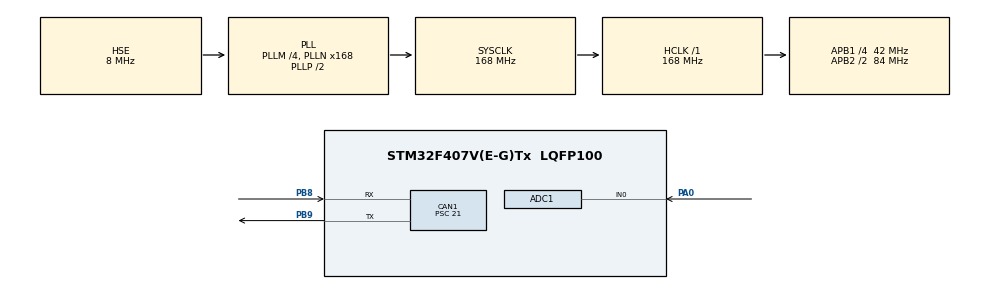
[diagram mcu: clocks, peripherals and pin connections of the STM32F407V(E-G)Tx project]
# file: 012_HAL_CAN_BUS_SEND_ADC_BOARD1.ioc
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Mcu.Family=STM32F4
RCC.PLLSourceVirtual=RCC_PLLSOURCE_HSE
PH0-OSC_IN.Signal=RCC_OSC_IN
Dma.ADC1.0.Instance=DMA2_Stream0
RCC.CortexFreq_Value=168000000
ADC1.ContinuousConvMode=ENABLE
CAN1.CalculateBaudRate=117647
RCC.APB1CLKDivider=RCC_HCLK_DIV4
RCC.SYSCLKSource=RCC_SYSCLKSOURCE_PLLCLK
ProjectManager.StackSize=0x400
PA0-WKUP.Signal=ADCx_IN0
Dma.ADC1.0.PeriphDataAlignment=DMA_PDATAALIGN_BYTE
CAN1.BS2=CAN_BS2_4TQ
ADC1.Channel-5\#ChannelRegularConversion=ADC_CHANNEL_0
CAN1.BS1=CAN_BS1_12TQ
ProjectManager.TargetToolchain=STM32CubeIDE
Dma.ADC1.0.Mode=DMA_CIRCULAR
RCC.HCLKFreq_Value=168000000
ADC1.Resolution=ADC_RESOLUTION_8B
PB9.Mode=CAN_Activate
Dma.ADC1.0.Priority=DMA_PRIORITY_LOW
RCC.APB2TimFreq_Value=168000000
Dma.ADC1.0.Direction=DMA_PERIPH_TO_MEMORY
ADC1.InjNumberOfConversion=0
NVIC.DMA2_Stream0_IRQn=true\:0\:0\:false\:false\:true\:false\:true
RCC.LSE_VALUE=32768
Dma.ADC1.0.MemDataAlignment=DMA_MDATAALIGN_BYTE
RCC.AHBFreq_Value=168000000
PH0-OSC_IN.Mode=HSE-External-Oscillator
RCC.HSE_VALUE=8000000
board=custom
RCC.VCOOutputFreq_Value=336000000
RCC.APB2Freq_Value=84000000
Dma.ADC1.0.PeriphInc=DMA_PINC_DISABLE
PH1-OSC_OUT.Signal=RCC_OSC_OUT
SH.ADCx_IN0.0=ADC1_IN0,IN0
ADC1.DMAContinuousRequests=ENABLE
ADC1.NbrOfConversion=1
Mcu.Name=STM32F407V(E-G)Tx
PH1-OSC_OUT.Mode=HSE-External-Oscillator
RCC.48MHZClocksFreq_Value=84000000
RCC.SYSCLKFreq_VALUE=168000000
CAN1.Prescaler=21
PB9.Signal=CAN1_TX
Mcu.Package=LQFP100
ADC1.master=1
Dma.ADC1.0.MemInc=DMA_MINC_ENABLE
ProjectManager.HeapSize=0x200
ADC1.SamplingTime-5\#ChannelRegularConversion=ADC_SAMPLETIME_56CYCLES
RCC.HSI_VALUE=16000000
NVIC.PriorityGroup=NVIC_PRIORITYGROUP_0
ADC1.NbrOfConversionFlag=1
RCC.APB2CLKDivider=RCC_HCLK_DIV2
RCC.PLLM=4
PB8.Mode=CAN_Activate
RCC.PLLN=168
RCC.APB1TimFreq_Value=84000000
PB8.Signal=CAN1_RX
Dma.ADC1.0.FIFOMode=DMA_FIFOMODE_DISABLE
RCC.APB1Freq_Value=42000000
Dma.Request0=ADC1
CAN1.CalculateTimeBit=8500.00
ADC1.Rank-5\#ChannelRegularConversion=1
NVIC.CAN1_RX0_IRQn=true\:0\:1\:false\:false\:true\:true\:true
CAN1.CalculateTimeQuantum=500.0

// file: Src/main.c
/* USER CODE BEGIN Header */
/**
  ******************************************************************************
  * @file           : main.c
  * @brief          : Main program body
  ******************************************************************************
  ** This notice applies to any and all portions of this file
  * that are not between comment pairs USER CODE BEGIN and
  * USER CODE END. Other portions of this file, whether
  * inserted by the user or by software development tools
  * are owned by their respective copyright owners.
  *
  * COPYRIGHT(c) 2021 STMicroelectronics
  *
  * Redistribution and use in source and binary forms, with or without modification,
  * are permitted provided that the following conditions are met:
  *   1. Redistributions of source code must retain the above copyright notice,
  *      this list of conditions and the following disclaimer.
  *   2. Redistributions in binary form must reproduce the above copyright notice,
  *      this list of conditions and the following disclaimer in the documentation
  *      and/or other materials provided with the distribution.
  *   3. Neither the name of STMicroelectronics nor the names of its contributors
  *      may be used to endorse or promote products derived from this software
  *      without specific prior written permission.
  *
  * THIS SOFTWARE IS PROVIDED BY THE COPYRIGHT HOLDERS AND CONTRIBUTORS "AS IS"
  * AND ANY EXPRESS OR IMPLIED WARRANTIES, INCLUDING, BUT NOT LIMITED TO, THE
  * IMPLIED WARRANTIES OF MERCHANTABILITY AND FITNESS FOR A PARTICULAR PURPOSE ARE
  * DISCLAIMED. IN NO EVENT SHALL THE COPYRIGHT HOLDER OR CONTRIBUTORS BE LIABLE
  * FOR ANY DIRECT, INDIRECT, INCIDENTAL, SPECIAL, EXEMPLARY, OR CONSEQUENTIAL
  * DAMAGES (INCLUDING, BUT NOT LIMITED TO, PROCUREMENT OF SUBSTITUTE GOODS OR
  * SERVICES; LOSS OF USE, DATA, OR PROFITS; OR BUSINESS INTERRUPTION) HOWEVER
  * CAUSED AND ON ANY THEORY OF LIABILITY, WHETHER IN CONTRACT, STRICT LIABILITY,
  * OR TORT (INCLUDING NEGLIGENCE OR OTHERWISE) ARISING IN ANY WAY OUT OF THE USE
  * OF THIS SOFTWARE, EVEN IF ADVISED OF THE POSSIBILITY OF SUCH DAMAGE.
  *
  ******************************************************************************
  */
/* USER CODE END Header */
#include "main.h"

ADC_HandleTypeDef hadc1;
DMA_HandleTypeDef hdma_adc1;

CAN_HandleTypeDef hcan1;

/* USER CODE BEGIN PV */
CAN_TxHeaderTypeDef pTxHeader; // Gönderecegimiz verileri için
CAN_FilterTypeDef sFilterConfig; // Filter Degerleri için

uint32_t pTxMailbox;
uint8_t adc_value;

/* USER CODE END PV */

void SystemClock_Config(void);
static void MX_GPIO_Init(void);
static void MX_DMA_Init(void);
static void MX_CAN1_Init(void);
static void MX_ADC1_Init(void);

int main(void)
{

  /* MCU Configuration--------------------------------------------------------*/

  /* Reset of all peripherals, Initializes the Flash interface and the Systick. */
  HAL_Init();

  /* Configure the system clock */
  SystemClock_Config();

  /* Initialize all configured peripherals */
  MX_GPIO_Init();
  MX_DMA_Init();
  MX_CAN1_Init();
  MX_ADC1_Init();
  /* USER CODE BEGIN 2 */

  	  // Set Transmit (pHeader) Parameters
  pTxHeader.DLC = 1;      // Specifies the length of the frame that will be transmitted. (Biz 1 bytlık veri gönderiyoruz)
  pTxHeader.IDE = CAN_ID_STD;       // Specifies the type of identifier for the message that will be transmitted.
  	  	  	  	  	  	  	  	  // @ref CAN_identifier_type içinde alabilecegi degerler mevcut.
  pTxHeader.RTR = CAN_RTR_DATA;     /*!< Specifies the type of frame for the message that will be transmitted.
                                      This parameter can be a value of @ref CAN_remote_transmission_request */
  pTxHeader.StdId = 0x0112;             /*!< Specifies the standard identifier. This parameter must be a number
 	  	  	  	  	  	  	          between Min_Data = 0 and Max_Data = 0x7FF. */

  	  // Set Filter Parameters
  sFilterConfig.FilterActivation = CAN_FILTER_ENABLE;
  sFilterConfig.FilterBank = 0;
  sFilterConfig.FilterFIFOAssignment = CAN_FILTER_FIFO0;
  sFilterConfig.FilterIdHigh     = 0x0000;
  sFilterConfig.FilterIdLow      = 0x0000;
  sFilterConfig.FilterMaskIdHigh = 0x0000; // 0x156 -- 0x15F arası degerleri alacaktır.
  sFilterConfig.FilterMaskIdLow  = 0x0000;
  sFilterConfig.FilterScale = CAN_FILTERSCALE_16BIT ;
  sFilterConfig.FilterMode = CAN_FILTERMODE_IDMASK;

  HAL_CAN_ConfigFilter(&hcan1, &sFilterConfig);

      // Start CAN communication
  HAL_CAN_Start(&hcan1);
  	  // Start ADC with DMA
  HAL_ADC_Start_DMA(&hadc1, &adc_value, 1); // 8bitlik deger verdik warning verebilir.

  /* USER CODE END 2 */

  /* Infinite loop */
  while (1)
  {

	 HAL_CAN_AddTxMessage(&hcan1, &pTxHeader, &adc_value, &pTxMailbox);
     HAL_Delay(50);

  }
}

void SystemClock_Config(void)
{
  RCC_OscInitTypeDef RCC_OscInitStruct = {0};
  RCC_ClkInitTypeDef RCC_ClkInitStruct = {0};

  /** Configure the main internal regulator output voltage
  */
  __HAL_RCC_PWR_CLK_ENABLE();
  __HAL_PWR_VOLTAGESCALING_CONFIG(PWR_REGULATOR_VOLTAGE_SCALE1);
  /** Initializes the RCC Oscillators according to the specified parameters
  * in the RCC_OscInitTypeDef structure.
  */
  RCC_OscInitStruct.OscillatorType = RCC_OSCILLATORTYPE_HSE;
  RCC_OscInitStruct.HSEState = RCC_HSE_ON;
  RCC_OscInitStruct.PLL.PLLState = RCC_PLL_ON;
  RCC_OscInitStruct.PLL.PLLSource = RCC_PLLSOURCE_HSE;
  RCC_OscInitStruct.PLL.PLLM = 4;
  RCC_OscInitStruct.PLL.PLLN = 168;
  RCC_OscInitStruct.PLL.PLLP = RCC_PLLP_DIV2;
  RCC_OscInitStruct.PLL.PLLQ = 4;
  if (HAL_RCC_OscConfig(&RCC_OscInitStruct) != HAL_OK)
  {
    Error_Handler();
  }
  /** Initializes the CPU, AHB and APB buses clocks
  */
  RCC_ClkInitStruct.ClockType = RCC_CLOCKTYPE_HCLK|RCC_CLOCKTYPE_SYSCLK
                              |RCC_CLOCKTYPE_PCLK1|RCC_CLOCKTYPE_PCLK2;
  RCC_ClkInitStruct.SYSCLKSource = RCC_SYSCLKSOURCE_PLLCLK;
  RCC_ClkInitStruct.AHBCLKDivider = RCC_SYSCLK_DIV1;
  RCC_ClkInitStruct.APB1CLKDivider = RCC_HCLK_DIV4;
  RCC_ClkInitStruct.APB2CLKDivider = RCC_HCLK_DIV2;

  if (HAL_RCC_ClockConfig(&RCC_ClkInitStruct, FLASH_LATENCY_5) != HAL_OK)
  {
    Error_Handler();
  }
}

static void MX_ADC1_Init(void)
{

  ADC_ChannelConfTypeDef sConfig = {0};

  /** Configure the global features of the ADC (Clock, Resolution, Data Alignment and number of conversion)
  */
  hadc1.Instance = ADC1;
  hadc1.Init.ClockPrescaler = ADC_CLOCK_SYNC_PCLK_DIV4;
  hadc1.Init.Resolution = ADC_RESOLUTION_8B;
  hadc1.Init.ScanConvMode = DISABLE;
  hadc1.Init.ContinuousConvMode = ENABLE;
  hadc1.Init.DiscontinuousConvMode = DISABLE;
  hadc1.Init.ExternalTrigConvEdge = ADC_EXTERNALTRIGCONVEDGE_NONE;
  hadc1.Init.ExternalTrigConv = ADC_SOFTWARE_START;
  hadc1.Init.DataAlign = ADC_DATAALIGN_RIGHT;
  hadc1.Init.NbrOfConversion = 1;
  hadc1.Init.DMAContinuousRequests = ENABLE;
  hadc1.Init.EOCSelection = ADC_EOC_SINGLE_CONV;
  if (HAL_ADC_Init(&hadc1) != HAL_OK)
  {
    Error_Handler();
  }
  /** Configure for the selected ADC regular channel its corresponding rank in the sequencer and its sample time.
  */
  sConfig.Channel = ADC_CHANNEL_0;
  sConfig.Rank = 1;
  sConfig.SamplingTime = ADC_SAMPLETIME_144CYCLES;
  if (HAL_ADC_ConfigChannel(&hadc1, &sConfig) != HAL_OK)
  {
    Error_Handler();
  }

}

static void MX_CAN1_Init(void)
{

  hcan1.Instance = CAN1;
  hcan1.Init.Prescaler = 21;
  hcan1.Init.Mode = CAN_MODE_NORMAL;
  hcan1.Init.SyncJumpWidth = CAN_SJW_1TQ;
  hcan1.Init.TimeSeg1 = CAN_BS1_12TQ;
  hcan1.Init.TimeSeg2 = CAN_BS2_4TQ;
  hcan1.Init.TimeTriggeredMode = DISABLE;
  hcan1.Init.AutoBusOff = DISABLE;
  hcan1.Init.AutoWakeUp = DISABLE;
  hcan1.Init.AutoRetransmission = DISABLE;
  hcan1.Init.ReceiveFifoLocked = DISABLE;
  hcan1.Init.TransmitFifoPriority = DISABLE;
  if (HAL_CAN_Init(&hcan1) != HAL_OK)
  {
    Error_Handler();
  }

}

static void MX_DMA_Init(void)
{

  /* DMA controller clock enable */
  __HAL_RCC_DMA2_CLK_ENABLE();

  /* DMA interrupt init */
  /* DMA2_Stream0_IRQn interrupt configuration */
  HAL_NVIC_SetPriority(DMA2_Stream0_IRQn, 0, 0);
  HAL_NVIC_EnableIRQ(DMA2_Stream0_IRQn);

}

static void MX_GPIO_Init(void)
{

  /* GPIO Ports Clock Enable */
  __HAL_RCC_GPIOH_CLK_ENABLE();
  __HAL_RCC_GPIOA_CLK_ENABLE();
  __HAL_RCC_GPIOB_CLK_ENABLE();

}

void Error_Handler(void)
{
}

/************************ (C) COPYRIGHT STMicroelectronics *****END OF FILE****/
